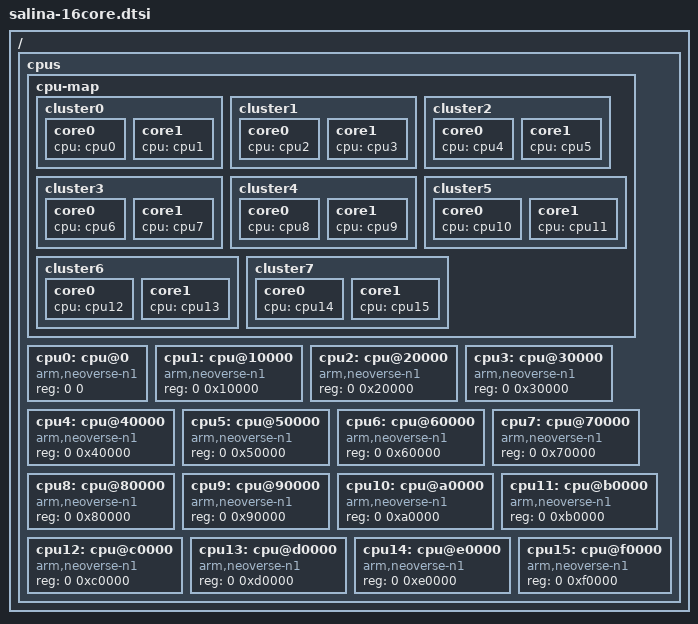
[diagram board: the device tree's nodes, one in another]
// SPDX-License-Identifier: (GPL-2.0-only or BSD-2-Clause)
/*
 * Copyright 2023-2024 Advanced Micro Devices, Inc.
 */

/ {
	cpus {
		#address-cells = <2>;
		#size-cells = <0>;

		cpu-map {
			cluster0 {
				core0 { cpu = <&cpu0>; };
				core1 { cpu = <&cpu1>; };
			};
			cluster1 {
				core0 { cpu = <&cpu2>; };
				core1 { cpu = <&cpu3>; };
			};
			cluster2 {
				core0 { cpu = <&cpu4>; };
				core1 { cpu = <&cpu5>; };
			};
			cluster3 {
				core0 { cpu = <&cpu6>; };
				core1 { cpu = <&cpu7>; };
			};
			cluster4 {
				core0 { cpu = <&cpu8>; };
				core1 { cpu = <&cpu9>; };
			};
			cluster5 {
				core0 { cpu = <&cpu10>; };
				core1 { cpu = <&cpu11>; };
			};
			cluster6 {
				core0 { cpu = <&cpu12>; };
				core1 { cpu = <&cpu13>; };
			};
			cluster7 {
				core0 { cpu = <&cpu14>; };
				core1 { cpu = <&cpu15>; };
			};
		};

		/* CLUSTER 0 */
		cpu0: cpu@0 {
			device_type = "cpu";
			compatible = "arm,neoverse-n1";
			reg = <0 0>;
		};

		cpu1: cpu@10000 {
			device_type = "cpu";
			compatible = "arm,neoverse-n1";
			reg = <0 0x10000>;
		};

		/* CLUSTER 1 */
		cpu2: cpu@20000 {
			device_type = "cpu";
			compatible = "arm,neoverse-n1";
			reg = <0 0x20000>;
		};

		cpu3: cpu@30000 {
			device_type = "cpu";
			compatible = "arm,neoverse-n1";
			reg = <0 0x30000>;
		};

		/* CLUSTER 2 */
		cpu4: cpu@40000 {
			device_type = "cpu";
			compatible = "arm,neoverse-n1";
			reg = <0 0x40000>;
		};

		cpu5: cpu@50000 {
			device_type = "cpu";
			compatible = "arm,neoverse-n1";
			reg = <0 0x50000>;
		};

		/* CLUSTER 3 */
		cpu6: cpu@60000 {
			device_type = "cpu";
			compatible = "arm,neoverse-n1";
			reg = <0 0x60000>;
		};

		cpu7: cpu@70000 {
			device_type = "cpu";
			compatible = "arm,neoverse-n1";
			reg = <0 0x70000>;
		};

		/* CLUSTER 4 */
		cpu8: cpu@80000 {
			device_type = "cpu";
			compatible = "arm,neoverse-n1";
			reg = <0 0x80000>;
		};

		cpu9: cpu@90000 {
			device_type = "cpu";
			compatible = "arm,neoverse-n1";
			reg = <0 0x90000>;
		};

		/* CLUSTER 5 */
		cpu10: cpu@a0000 {
			device_type = "cpu";
			compatible = "arm,neoverse-n1";
			reg = <0 0xa0000>;
		};

		cpu11: cpu@b0000 {
			device_type = "cpu";
			compatible = "arm,neoverse-n1";
			reg = <0 0xb0000>;
		};

		/* CLUSTER 6 */
		cpu12: cpu@c0000 {
			device_type = "cpu";
			compatible = "arm,neoverse-n1";
			reg = <0 0xc0000>;
		};

		cpu13: cpu@d0000 {
			device_type = "cpu";
			compatible = "arm,neoverse-n1";
			reg = <0 0xd0000>;
		};

		/* CLUSTER 7 */
		cpu14: cpu@e0000 {
			device_type = "cpu";
			compatible = "arm,neoverse-n1";
			reg = <0 0xe0000>;
		};

		cpu15: cpu@f0000 {
			device_type = "cpu";
			compatible = "arm,neoverse-n1";
			reg = <0 0xf0000>;
		};
	};
};
